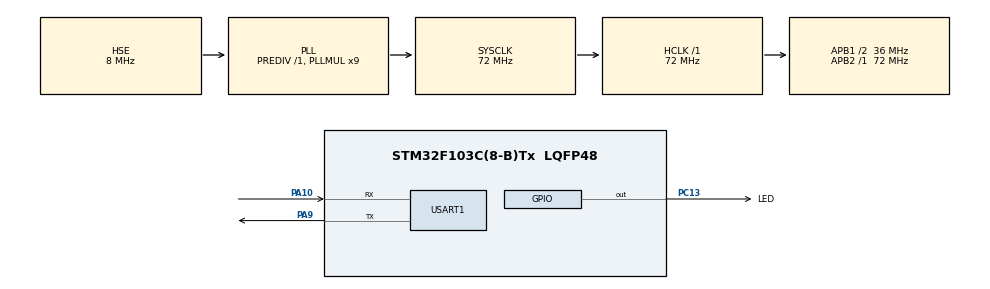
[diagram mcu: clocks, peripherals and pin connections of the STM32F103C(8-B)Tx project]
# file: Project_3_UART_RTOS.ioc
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FREERTOS.BinarySemaphores01=received_done,Dynamic,NULL,Available
FREERTOS.Queues01=received_command,16,uint16_t,0,Dynamic,NULL,NULL
FREERTOS.Tasks01=UART_Task,40,128,Start_UART_Task,Default,NULL,Dynamic,NULL,NULL;Process_task,24,128,Start_Process_Task,Default,NULL,Dynamic,NULL,NULL;LEDControl_task,8,128,Start_LEDControl_Task,Default,NULL,Dynamic,NULL,NULL;Log_task,8,128,Start_Log_Task,Default,NULL,Dynamic,NULL,NULL
Mcu.Family=STM32F1
Mcu.Name=STM32F103C(8-B)Tx
Mcu.Package=LQFP48
NVIC.PriorityGroup=NVIC_PRIORITYGROUP_4
NVIC.TIM4_IRQn=true\:15\:0\:false\:false\:true\:false\:false\:true\:true
NVIC.TimeBase=TIM4_IRQn
NVIC.TimeBaseIP=TIM4
NVIC.USART1_IRQn=true\:5\:0\:false\:false\:true\:true\:true\:true\:true
PA10.Mode=Asynchronous
PA10.Signal=USART1_RX
PA13.Mode=Serial_Wire
PA13.Signal=SYS_JTMS-SWDIO
PA14.Mode=Serial_Wire
PA14.Signal=SYS_JTCK-SWCLK
PA9.Mode=Asynchronous
PA9.Signal=USART1_TX
PC13-TAMPER-RTC.GPIO_Label=LED
PC13-TAMPER-RTC.PinState=GPIO_PIN_SET
PC13-TAMPER-RTC.Signal=GPIO_Output
PD0-OSC_IN.Mode=HSE-External-Oscillator
PD0-OSC_IN.Signal=RCC_OSC_IN
PD1-OSC_OUT.Mode=HSE-External-Oscillator
PD1-OSC_OUT.Signal=RCC_OSC_OUT
ProjectManager.HeapSize=0x200
ProjectManager.StackSize=0x400
ProjectManager.TargetToolchain=MDK-ARM V5.32
RCC.AHBFreq_Value=72000000
RCC.APB1CLKDivider=RCC_HCLK_DIV2
RCC.APB1Freq_Value=36000000
RCC.APB1TimFreq_Value=72000000
RCC.APB2Freq_Value=72000000
RCC.APB2TimFreq_Value=72000000
RCC.HCLKFreq_Value=72000000
RCC.PLLMUL=RCC_PLL_MUL9
RCC.PLLSourceVirtual=RCC_PLLSOURCE_HSE
RCC.SYSCLKFreq_VALUE=72000000
RCC.SYSCLKSource=RCC_SYSCLKSOURCE_PLLCLK
RCC.USBFreq_Value=72000000
USART1.VirtualMode=VM_ASYNC
VP_FREERTOS_VS_CMSIS_V2.Mode=CMSIS_V2
VP_SYS_VS_tim4.Mode=TIM4
board=custom

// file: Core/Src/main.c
/* USER CODE BEGIN Header */
/**
  ******************************************************************************
  * @file           : main.c
  * @brief          : Main program body
  ******************************************************************************
  * @attention
  *
  * Copyright (c) 2026 STMicroelectronics.
  * All rights reserved.
  *
  * This software is licensed under terms that can be found in the LICENSE file
  * in the root directory of this software component.
  * If no LICENSE file comes with this software, it is provided AS-IS.
  *
  ******************************************************************************
  */
/* USER CODE END Header */
#include "FreeRTOS.h"
#include "main.h"
#include "cmsis_os.h"
#include <string.h>
#include "queue.h"

/* USER CODE BEGIN PM */
enum {
	LED_ON = 0,
	LED_OFF,
	LOG,
	ERROR_COMMAND,
	UNKNOWN_COMMAND,
};
/* USER CODE END PM */

UART_HandleTypeDef huart1;

/* Definitions for UART_Task */
osThreadId_t UART_TaskHandle;
const osThreadAttr_t UART_Task_attributes = {
  .name = "UART_Task",
  .stack_size = 128 * 4,
  .priority = (osPriority_t) osPriorityHigh,
};
/* Definitions for Process_task */
osThreadId_t Process_taskHandle;
const osThreadAttr_t Process_task_attributes = {
  .name = "Process_task",
  .stack_size = 128 * 4,
  .priority = (osPriority_t) osPriorityNormal,
};
/* Definitions for LEDControl_task */
osThreadId_t LEDControl_taskHandle;
const osThreadAttr_t LEDControl_task_attributes = {
  .name = "LEDControl_task",
  .stack_size = 128 * 4,
  .priority = (osPriority_t) osPriorityLow,
};
/* Definitions for Log_task */
osThreadId_t Log_taskHandle;
const osThreadAttr_t Log_task_attributes = {
  .name = "Log_task",
  .stack_size = 128 * 4,
  .priority = (osPriority_t) osPriorityLow,
};

/* Definitions for received_ISR */
QueueHandle_t received_ISRHandle;

/* Definitions for received_command */
osMessageQueueId_t received_commandHandle;
const osMessageQueueAttr_t received_command_attributes = {
  .name = "received_command"
};

/* Definitions for led_control */
osMessageQueueId_t led_controlHandle;
const osMessageQueueAttr_t led_control_attributes = {
  .name = "led_control"
};

/* Definitions for log */
osMessageQueueId_t logHandle;
const osMessageQueueAttr_t log_attributes = {
  .name = "log"
};

void SystemClock_Config(void);
static void MX_GPIO_Init(void);
static void MX_USART1_UART_Init(void);
void Start_UART_Task(void *argument);
void Start_Process_Task(void *argument);
void Start_LEDControl_Task(void *argument);
void Start_Log_Task(void *argument);

/* USER CODE BEGIN 0 */

uint8_t rx_byte; //store byte from RX ISR
volatile uint8_t tx_busy_flag = 0; //tx busy flag
uint8_t error_flag = 0; //overflow flag
uint8_t received_command_done = 0;
void HAL_UART_TxCpltCallback(UART_HandleTypeDef *huart) {
	if(huart->Instance == USART1) {
		tx_busy_flag = 0;
	}
}
void HAL_UART_RxCpltCallback(UART_HandleTypeDef *huart) {
	if(huart->Instance == USART1) {
		BaseType_t xHigherPriorityTaskWoken = pdFALSE;
		xQueueSendFromISR(received_ISRHandle,&rx_byte, &xHigherPriorityTaskWoken);
		HAL_UART_Receive_IT(&huart1, &rx_byte, 1);
		portYIELD_FROM_ISR(xHigherPriorityTaskWoken);
	}
}
/* USER CODE END 0 */

int main(void)
{

  /* MCU Configuration--------------------------------------------------------*/

  /* Reset of all peripherals, Initializes the Flash interface and the Systick. */
  HAL_Init();

  /* Configure the system clock */
  SystemClock_Config();

  /* Initialize all configured peripherals */
  MX_GPIO_Init();
  MX_USART1_UART_Init();
  /* USER CODE BEGIN 2 */
	HAL_UART_Receive_IT(&huart1, &rx_byte, 1);
  /* USER CODE END 2 */

  /* Init scheduler */
  osKernelInitialize();

  /* Create the semaphores(s) */
  /* creation of received_done */

  /* Create the queue(s) */
	/* creation of received_ISR */
  received_ISRHandle = xQueueCreate(64, sizeof(uint8_t));
  /* creation of received_command */
  received_commandHandle = osMessageQueueNew (16, sizeof(uint16_t), &received_command_attributes);
	/* creation of led_control */
  led_controlHandle = osMessageQueueNew (16, sizeof(uint16_t), &led_control_attributes);
	/* creation of log */
  logHandle = osMessageQueueNew (16, sizeof(uint16_t), &log_attributes);

  /* Create the thread(s) */
  /* creation of UART_Task */
  UART_TaskHandle = osThreadNew(Start_UART_Task, NULL, &UART_Task_attributes);

  /* creation of Process_task */
  Process_taskHandle = osThreadNew(Start_Process_Task, NULL, &Process_task_attributes);

  /* creation of LEDControl_task */
  LEDControl_taskHandle = osThreadNew(Start_LEDControl_Task, NULL, &LEDControl_task_attributes);

  /* creation of Log_task */
  Log_taskHandle = osThreadNew(Start_Log_Task, NULL, &Log_task_attributes);

  /* Start scheduler */
  osKernelStart();

  /* We should never get here as control is now taken by the scheduler */

  /* Infinite loop */
  while (1)
  {

  }
}

void SystemClock_Config(void)
{
  RCC_OscInitTypeDef RCC_OscInitStruct = {0};
  RCC_ClkInitTypeDef RCC_ClkInitStruct = {0};

  /** Initializes the RCC Oscillators according to the specified parameters
  * in the RCC_OscInitTypeDef structure.
  */
  RCC_OscInitStruct.OscillatorType = RCC_OSCILLATORTYPE_HSE;
  RCC_OscInitStruct.HSEState = RCC_HSE_ON;
  RCC_OscInitStruct.HSEPredivValue = RCC_HSE_PREDIV_DIV1;
  RCC_OscInitStruct.HSIState = RCC_HSI_ON;
  RCC_OscInitStruct.PLL.PLLState = RCC_PLL_ON;
  RCC_OscInitStruct.PLL.PLLSource = RCC_PLLSOURCE_HSE;
  RCC_OscInitStruct.PLL.PLLMUL = RCC_PLL_MUL9;
  if (HAL_RCC_OscConfig(&RCC_OscInitStruct) != HAL_OK)
  {
    Error_Handler();
  }

  /** Initializes the CPU, AHB and APB buses clocks
  */
  RCC_ClkInitStruct.ClockType = RCC_CLOCKTYPE_HCLK|RCC_CLOCKTYPE_SYSCLK
                              |RCC_CLOCKTYPE_PCLK1|RCC_CLOCKTYPE_PCLK2;
  RCC_ClkInitStruct.SYSCLKSource = RCC_SYSCLKSOURCE_PLLCLK;
  RCC_ClkInitStruct.AHBCLKDivider = RCC_SYSCLK_DIV1;
  RCC_ClkInitStruct.APB1CLKDivider = RCC_HCLK_DIV2;
  RCC_ClkInitStruct.APB2CLKDivider = RCC_HCLK_DIV1;

  if (HAL_RCC_ClockConfig(&RCC_ClkInitStruct, FLASH_LATENCY_2) != HAL_OK)
  {
    Error_Handler();
  }
}

static void MX_USART1_UART_Init(void)
{

  huart1.Instance = USART1;
  huart1.Init.BaudRate = 115200;
  huart1.Init.WordLength = UART_WORDLENGTH_8B;
  huart1.Init.StopBits = UART_STOPBITS_1;
  huart1.Init.Parity = UART_PARITY_NONE;
  huart1.Init.Mode = UART_MODE_TX_RX;
  huart1.Init.HwFlowCtl = UART_HWCONTROL_NONE;
  huart1.Init.OverSampling = UART_OVERSAMPLING_16;
  if (HAL_UART_Init(&huart1) != HAL_OK)
  {
    Error_Handler();
  }

}

static void MX_GPIO_Init(void)
{
  GPIO_InitTypeDef GPIO_InitStruct = {0};

  /* GPIO Ports Clock Enable */
  __HAL_RCC_GPIOC_CLK_ENABLE();
  __HAL_RCC_GPIOD_CLK_ENABLE();
  __HAL_RCC_GPIOA_CLK_ENABLE();

  /*Configure GPIO pin Output Level */
  HAL_GPIO_WritePin(LED_GPIO_Port, LED_Pin, GPIO_PIN_SET);

  /*Configure GPIO pin : LED_Pin */
  GPIO_InitStruct.Pin = LED_Pin;
  GPIO_InitStruct.Mode = GPIO_MODE_OUTPUT_PP;
  GPIO_InitStruct.Pull = GPIO_NOPULL;
  GPIO_InitStruct.Speed = GPIO_SPEED_FREQ_LOW;
  HAL_GPIO_Init(LED_GPIO_Port, &GPIO_InitStruct);

}

void Start_UART_Task(void *argument)
{
  /* USER CODE BEGIN 5 */
  /* Infinite loop */
	uint8_t byte = 0;
	static char command[8] = {0};
	uint8_t index = 0;
  for(;;)

  {
		if(xQueueReceive(received_ISRHandle,&byte,portMAX_DELAY) == pdTRUE){
			if(byte == '\r') {
				command[index] = '\0';
				uint8_t cmd = 0;
				if (error_flag) {
					cmd = ERROR_COMMAND;
					error_flag = 0;
				} else {
					if (strcmp(command,"LED_ON") == 0) {
						cmd = LED_ON;
					} else if (strcmp(command,"LED_OFF") == 0) {
						cmd = LED_OFF;
					} else if (strcmp(command,"LOG") == 0) {
						cmd = LOG;
					} else {
						cmd = UNKNOWN_COMMAND;
					}
				}
				osMessageQueuePut(received_commandHandle,&cmd,0,osWaitForever);
				index = 0;
			} else {
				if (index < sizeof(command) - 1) {
					command[index++] = byte;
				} else { //overflow
					error_flag = 1;
					memset(command, 0,sizeof(command));
					index = 0;
				}
			}
		}
  }
  /* USER CODE END 5 */
}

void Start_Process_Task(void *argument)
{
  /* USER CODE BEGIN Start_Process_Task */
  /* Infinite loop */
	uint8_t command = 0;
  for(;;)
  {
		osMessageQueueGet(received_commandHandle,&command,NULL,osWaitForever);
		switch (command) {
			case LED_ON:
				osMessageQueuePut(led_controlHandle,&command,0,0);
				osMessageQueuePut(logHandle,&command,0,0);
				break;
			case LED_OFF:
				osMessageQueuePut(led_controlHandle,&command,0,0);
				osMessageQueuePut(logHandle,&command,0,0);
				break;
			case LOG:
				osMessageQueuePut(logHandle,&command,0,0);
				break;
			case ERROR_COMMAND:
				osMessageQueuePut(logHandle,&command,0,0);
				break;
			case UNKNOWN_COMMAND:
				osMessageQueuePut(logHandle,&command,0,0);
				break;
			default:
				break;
		}
  }
  /* USER CODE END Start_Process_Task */
}

void Start_LEDControl_Task(void *argument)
{
  /* USER CODE BEGIN Start_LEDControl_Task */
  /* Infinite loop */
	int8_t buffer = 0;
  for(;;)
  {
		osMessageQueueGet(led_controlHandle,&buffer,NULL,osWaitForever);
		switch (buffer) {
			case LED_OFF:
				HAL_GPIO_WritePin(GPIOC,GPIO_PIN_13,1);
				break;
			case LED_ON:
				HAL_GPIO_WritePin(GPIOC,GPIO_PIN_13,0);
				break;
			default:
				break;
		}
  }
  /* USER CODE END Start_LEDControl_Task */
}

void Start_Log_Task(void *argument)
{
  /* USER CODE BEGIN Start_Log_Task */
  /* Infinite loop */
	int8_t buffer = 0;
  for(;;)
  {
		osMessageQueueGet(logHandle,&buffer,NULL,osWaitForever);
		if (tx_busy_flag == 0) {
			tx_busy_flag = 1;
			switch (buffer) {
				case LED_OFF:
					HAL_UART_Transmit_IT(&huart1,(const uint8_t*)"OFF_ok\n",strlen("OFF_ok\n"));
					break;
				case LED_ON:
					HAL_UART_Transmit_IT(&huart1,(const uint8_t*)"ON_ok\n",strlen("ON_ok\n"));
					break;
				case ERROR_COMMAND:
					HAL_UART_Transmit_IT(&huart1,(const uint8_t*)"error_command\n",strlen("error_command\n"));
					break;
				case UNKNOWN_COMMAND:
					HAL_UART_Transmit_IT(&huart1,(const uint8_t*)"unknown_command\n",strlen("unknown_command\n"));
					break;
				case LOG:
					const char *msg = HAL_GPIO_ReadPin(GPIOC, GPIO_PIN_13) ?
                  "LED is OFF\n" : "LED is ON\n";

					HAL_UART_Transmit_IT(&huart1, (uint8_t *)msg, strlen(msg));
					break;
				default:
					break;
			}
		}
  }
  /* USER CODE END Start_Log_Task */
}

void HAL_TIM_PeriodElapsedCallback(TIM_HandleTypeDef *htim)
{
  if (htim->Instance == TIM4)
  {
    HAL_IncTick();
  }
}

void Error_Handler(void)
{
  __disable_irq();
  while (1)
  {
  }
}
